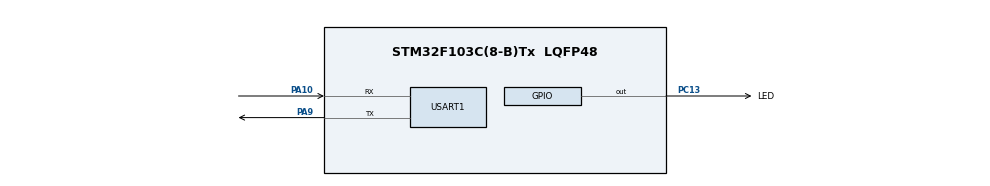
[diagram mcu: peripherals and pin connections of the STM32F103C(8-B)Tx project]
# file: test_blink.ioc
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FREERTOS.Events01=event_flag_hw_reset,Dynamic,NULL
FREERTOS.Tasks01=hw_reset_task,24,128,hw_reset_function,Default,NULL,Dynamic,NULL,NULL
Mcu.Family=STM32F1
Mcu.Name=STM32F103C(8-B)Tx
Mcu.Package=LQFP48
NVIC.PriorityGroup=NVIC_PRIORITYGROUP_4
NVIC.RTC_IRQn=true\:5\:0\:false\:false\:true\:true\:true\:true\:true
NVIC.TIM4_IRQn=true\:15\:0\:false\:false\:true\:false\:false\:true\:true
NVIC.TimeBase=TIM4_IRQn
NVIC.TimeBaseIP=TIM4
NVIC.USART1_IRQn=true\:5\:0\:false\:false\:true\:true\:true\:true\:true
PA10.Mode=Asynchronous
PA10.Signal=USART1_RX
PA13.Mode=Serial_Wire
PA13.Signal=SYS_JTMS-SWDIO
PA14.Mode=Serial_Wire
PA14.Signal=SYS_JTCK-SWCLK
PA9.Mode=Asynchronous
PA9.Signal=USART1_TX
PC13-TAMPER-RTC.GPIO_Label=LED
PC13-TAMPER-RTC.Signal=GPIO_Output
ProjectManager.HeapSize=0x200
ProjectManager.StackSize=0x400
ProjectManager.TargetToolchain=STM32CubeIDE
RCC.APB1Freq_Value=8000000
RCC.APB2Freq_Value=8000000
RTC.Format=RTC_FORMAT_BCD
USART1.VirtualMode=VM_ASYNC
VP_FREERTOS_VS_CMSIS_V2.Mode=CMSIS_V2
VP_RTC_No_RTC_Output.Mode=RTC_OUT_NO
VP_RTC_VS_RTC_Activate.Mode=RTC_Enabled
VP_RTC_VS_RTC_Calendar.Mode=RTC_Calendar
VP_SYS_VS_tim4.Mode=TIM4
board=custom

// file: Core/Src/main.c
/* USER CODE BEGIN Header */
/**
  ******************************************************************************
  * @file           : main.c
  * @brief          : Main program body
  ******************************************************************************
  * @attention
  *
  * Copyright (c) 2023 STMicroelectronics.
  * All rights reserved.
  *
  * This software is licensed under terms that can be found in the LICENSE file
  * in the root directory of this software component.
  * If no LICENSE file comes with this software, it is provided AS-IS.
  *
  ******************************************************************************
  */
/* USER CODE END Header */
#include "main.h"
#include "cmsis_os.h"

RTC_HandleTypeDef hrtc;

UART_HandleTypeDef huart1;

/* Definitions for hw_reset_task */
osThreadId_t hw_reset_taskHandle;
const osThreadAttr_t hw_reset_task_attributes = {
  .name = "hw_reset_task",
  .stack_size = 128 * 4,
  .priority = (osPriority_t) osPriorityNormal,
};
/* Definitions for event_flag_hw_reset */
osEventFlagsId_t event_flag_hw_resetHandle;
const osEventFlagsAttr_t event_flag_hw_reset_attributes = {
  .name = "event_flag_hw_reset"
};

void SystemClock_Config(void);
static void MX_GPIO_Init(void);
static void MX_RTC_Init(void);
static void MX_USART1_UART_Init(void);
void hw_reset_function(void *argument);

int main(void)
{

  /* MCU Configuration--------------------------------------------------------*/

  /* Reset of all peripherals, Initializes the Flash interface and the Systick. */
  HAL_Init();

  /* Configure the system clock */
  SystemClock_Config();

  /* Initialize all configured peripherals */
  MX_GPIO_Init();
  MX_RTC_Init();
  MX_USART1_UART_Init();

  /* Init scheduler */
  osKernelInitialize();

  /* Create the thread(s) */
  /* creation of hw_reset_task */
  hw_reset_taskHandle = osThreadNew(hw_reset_function, NULL, &hw_reset_task_attributes);

  /* Create the event(s) */
  /* creation of event_flag_hw_reset */
  event_flag_hw_resetHandle = osEventFlagsNew(&event_flag_hw_reset_attributes);

  /* Start scheduler */
  osKernelStart();

  /* We should never get here as control is now taken by the scheduler */
  /* Infinite loop */
  while (1)
  {

  }
}

void SystemClock_Config(void)
{
  RCC_OscInitTypeDef RCC_OscInitStruct = {0};
  RCC_ClkInitTypeDef RCC_ClkInitStruct = {0};
  RCC_PeriphCLKInitTypeDef PeriphClkInit = {0};

  /** Initializes the RCC Oscillators according to the specified parameters
  * in the RCC_OscInitTypeDef structure.
  */
  RCC_OscInitStruct.OscillatorType = RCC_OSCILLATORTYPE_HSI|RCC_OSCILLATORTYPE_LSI;
  RCC_OscInitStruct.HSIState = RCC_HSI_ON;
  RCC_OscInitStruct.HSICalibrationValue = RCC_HSICALIBRATION_DEFAULT;
  RCC_OscInitStruct.LSIState = RCC_LSI_ON;
  RCC_OscInitStruct.PLL.PLLState = RCC_PLL_NONE;
  if (HAL_RCC_OscConfig(&RCC_OscInitStruct) != HAL_OK)
  {
    Error_Handler();
  }

  /** Initializes the CPU, AHB and APB buses clocks
  */
  RCC_ClkInitStruct.ClockType = RCC_CLOCKTYPE_HCLK|RCC_CLOCKTYPE_SYSCLK
                              |RCC_CLOCKTYPE_PCLK1|RCC_CLOCKTYPE_PCLK2;
  RCC_ClkInitStruct.SYSCLKSource = RCC_SYSCLKSOURCE_HSI;
  RCC_ClkInitStruct.AHBCLKDivider = RCC_SYSCLK_DIV1;
  RCC_ClkInitStruct.APB1CLKDivider = RCC_HCLK_DIV1;
  RCC_ClkInitStruct.APB2CLKDivider = RCC_HCLK_DIV1;

  if (HAL_RCC_ClockConfig(&RCC_ClkInitStruct, FLASH_LATENCY_0) != HAL_OK)
  {
    Error_Handler();
  }
  PeriphClkInit.PeriphClockSelection = RCC_PERIPHCLK_RTC;
  PeriphClkInit.RTCClockSelection = RCC_RTCCLKSOURCE_LSI;
  if (HAL_RCCEx_PeriphCLKConfig(&PeriphClkInit) != HAL_OK)
  {
    Error_Handler();
  }
}

static void MX_RTC_Init(void)
{

  RTC_TimeTypeDef sTime = {0};
  RTC_DateTypeDef DateToUpdate = {0};

  /** Initialize RTC Only
  */
  hrtc.Instance = RTC;
  hrtc.Init.AsynchPrediv = RTC_AUTO_1_SECOND;
  hrtc.Init.OutPut = RTC_OUTPUTSOURCE_NONE;
  if (HAL_RTC_Init(&hrtc) != HAL_OK)
  {
    Error_Handler();
  }

  /** Initialize RTC and set the Time and Date
  */
  sTime.Hours = 0x0;
  sTime.Minutes = 0x0;
  sTime.Seconds = 0x0;

  if (HAL_RTC_SetTime(&hrtc, &sTime, RTC_FORMAT_BCD) != HAL_OK)
  {
    Error_Handler();
  }
  DateToUpdate.WeekDay = RTC_WEEKDAY_MONDAY;
  DateToUpdate.Month = RTC_MONTH_JANUARY;
  DateToUpdate.Date = 0x1;
  DateToUpdate.Year = 0x0;

  if (HAL_RTC_SetDate(&hrtc, &DateToUpdate, RTC_FORMAT_BCD) != HAL_OK)
  {
    Error_Handler();
  }

}

static void MX_USART1_UART_Init(void)
{

  huart1.Instance = USART1;
  huart1.Init.BaudRate = 115200;
  huart1.Init.WordLength = UART_WORDLENGTH_8B;
  huart1.Init.StopBits = UART_STOPBITS_1;
  huart1.Init.Parity = UART_PARITY_NONE;
  huart1.Init.Mode = UART_MODE_TX_RX;
  huart1.Init.HwFlowCtl = UART_HWCONTROL_NONE;
  huart1.Init.OverSampling = UART_OVERSAMPLING_16;
  if (HAL_UART_Init(&huart1) != HAL_OK)
  {
    Error_Handler();
  }

}

static void MX_GPIO_Init(void)
{
  GPIO_InitTypeDef GPIO_InitStruct = {0};

  /* GPIO Ports Clock Enable */
  __HAL_RCC_GPIOC_CLK_ENABLE();
  __HAL_RCC_GPIOA_CLK_ENABLE();

  /*Configure GPIO pin Output Level */
  HAL_GPIO_WritePin(LED_GPIO_Port, LED_Pin, GPIO_PIN_RESET);

  /*Configure GPIO pin : LED_Pin */
  GPIO_InitStruct.Pin = LED_Pin;
  GPIO_InitStruct.Mode = GPIO_MODE_OUTPUT_PP;
  GPIO_InitStruct.Pull = GPIO_NOPULL;
  GPIO_InitStruct.Speed = GPIO_SPEED_FREQ_LOW;
  HAL_GPIO_Init(LED_GPIO_Port, &GPIO_InitStruct);

}

void hw_reset_function(void *argument)
{
  /* USER CODE BEGIN 5 */
  uint8_t sayHi[] = "hello GD";
  HAL_UART_Transmit(&huart1, sayHi, sizeof(sayHi), 1000);

  /* Infinite loop */
  for(;;)
  {
	HAL_GPIO_TogglePin(LED_GPIO_Port, LED_Pin);
	osDelay(1000);

  }
  /* USER CODE END 5 */
}

void HAL_TIM_PeriodElapsedCallback(TIM_HandleTypeDef *htim)
{
  if (htim->Instance == TIM4) {
    HAL_IncTick();
  }
}

void Error_Handler(void)
{
  __disable_irq();
  while (1)
  {
  }
}
